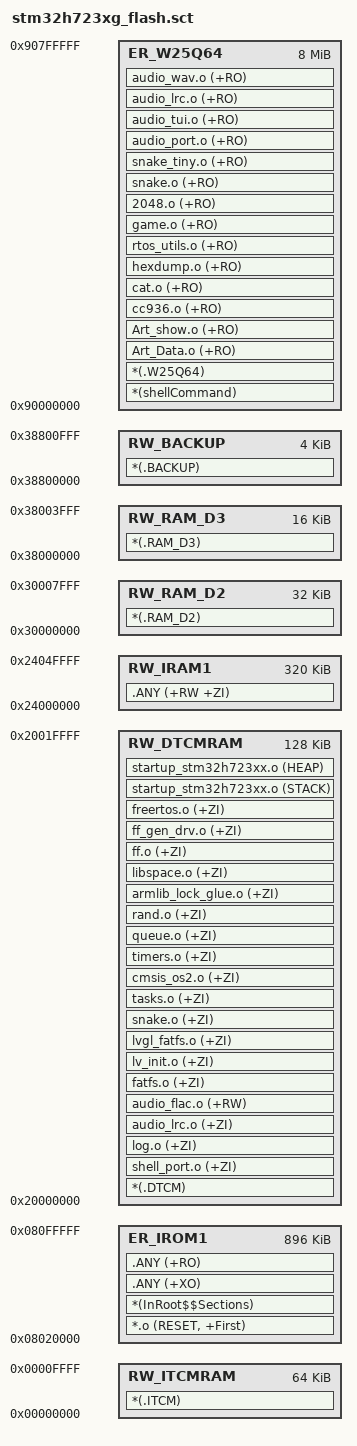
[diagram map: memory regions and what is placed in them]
; 加载区 起始地址 大小
LR_IROM1 0x08020000 0x000E0000  {
  ; 加载地址 = 执行地址
  ER_IROM1 0x08020000 0x000E0000  {
   *.o (RESET, +First)
   *(InRoot$$Sections)
   .ANY (+XO)
   .ANY (+RO)
  }

  ; 内部RAM区 起始地址 大小
  RW_IRAM1 0x24000000 0x00050000  {
   .ANY (+RW +ZI)
  }

  ; DTCM RAM区 起始地址 大小
  RW_DTCMRAM 0x20000000 0x00020000  {
    *(.DTCM)
    shell_port.o (+ZI)   ; shell实例
    log.o (+ZI)          ; shell日志缓冲
    audio_lrc.o (+ZI)    ; 歌词解析缓冲
    audio_flac.o (+RW)   ; FLAC查找表，仓库只读数据没有添加const关键字
    fatfs.o (+ZI)        ; FatFs对象
    lv_init.o (+ZI)      ; LVGL全局状态
    lvgl_fatfs.o (+ZI)   ; FatFs驱动对象
    snake.o (+ZI)        ; 贪吃蛇缓冲

    tasks.o (+ZI)            ; 内核就绪表/延时链表
    cmsis_os2.o (+ZI)        ; Idle/Timer任务栈与TCB
    timers.o (+ZI)           ; 定时器命令队列
    queue.o (+ZI)            ; 队列注册表
    rand.o (+ZI)             ; C库rand状态
    armlib_lock_glue.o (+ZI) ; C库锁
    libspace.o (+ZI)         ; C库内部空间
    ff.o (+ZI)               ; FatFs内部
    ff_gen_drv.o (+ZI)       ; FatFs驱动器表
    freertos.o (+ZI)                ; 静态任务栈与TCB

    startup_stm32h723xx.o (STACK)   ; 主栈
    startup_stm32h723xx.o (HEAP)    ; C库堆
  }

  ; RAM_D2区 起始地址 大小
  RW_RAM_D2 0x30000000 0x00008000  {
    *(.RAM_D2)
  }

  ; RAM_D3区 起始地址 大小
  RW_RAM_D3 0x38000000 0x00004000  {
    *(.RAM_D3)
  }

  ; ITCM RAM区 起始地址 大小
  RW_ITCMRAM 0x00000000 0x00010000  {
    *(.ITCM)
  }

  ; BACKUP ARM区 起始地址 大小
  RW_BACKUP 0x38800000 0x00001000  {
    *(.BACKUP)
  }
}

; 外部W25Q64 Flash区 起始地址 大小
LR_W25Q64 0x90000000 0x00800000 {
    ER_W25Q64 0x90000000 0x00800000 {
      *(shellCommand)
      *(.W25Q64)

      Art_Data.o (+RO)      ; 图片数据
      Art_show.o (+RO)      ; 图片显示函数

      cc936.o (+RO)         ; CC936模块驱动

      cat.o (+RO)           ; cat命令
      hexdump.o (+RO)       ; hexdump命令

      rtos_utils.o (+RO)    ; RTOS工具集

      game.o (+RO)         	; game shell命令组入口
      2048.o (+RO)         	; 2048游戏
      snake.o (+RO)        	; 贪吃蛇
      snake_tiny.o (+RO)   	; 贪吃蛇
      ; conf.o (+RO)         	; 配置数据
      ; gameover.o (+RO)     	; 结束界面
      ; inter.o (+RO)        	; 界面元素
      ; twister.o (+RO)      	; 旋转特效

      audio_port.o (+RO)    ; 播放器接口
      audio_tui.o (+RO)     ; 播放器tui
      audio_lrc.o (+RO)     ; 播放器LRC解析
      audio_wav.o (+RO)     ; 播放器WAV解码
    }

}
